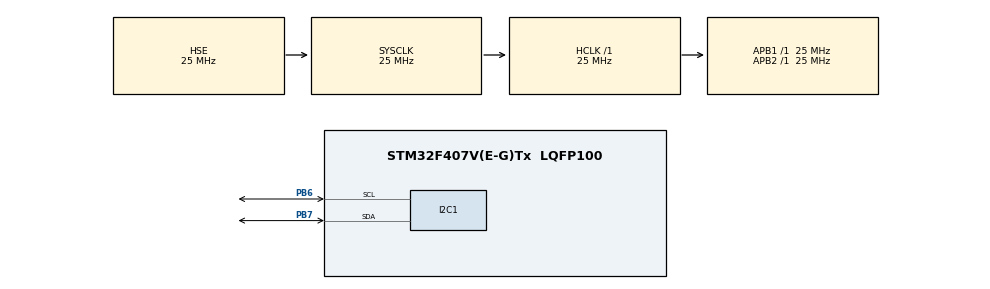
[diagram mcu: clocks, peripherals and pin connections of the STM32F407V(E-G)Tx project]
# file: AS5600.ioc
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I2C1.I2C_Mode=I2C_Standard
Mcu.Family=STM32F4
Mcu.Name=STM32F407V(E-G)Tx
Mcu.Package=LQFP100
NVIC.PriorityGroup=NVIC_PRIORITYGROUP_4
PA13.Mode=Serial_Wire
PA13.Signal=SYS_JTMS-SWDIO
PA14.Mode=Serial_Wire
PA14.Signal=SYS_JTCK-SWCLK
PB6.Mode=I2C
PB6.Signal=I2C1_SCL
PB7.Mode=I2C
PB7.Signal=I2C1_SDA
PH0-OSC_IN.Mode=HSE-External-Oscillator
PH0-OSC_IN.Signal=RCC_OSC_IN
PH1-OSC_OUT.Mode=HSE-External-Oscillator
PH1-OSC_OUT.Signal=RCC_OSC_OUT
ProjectManager.HeapSize=0x200
ProjectManager.StackSize=0x400
ProjectManager.TargetToolchain=MDK-ARM V5.32
RCC.48MHZClocksFreq_Value=75000000
RCC.AHBFreq_Value=25000000
RCC.APB1Freq_Value=25000000
RCC.APB1TimFreq_Value=25000000
RCC.APB2Freq_Value=25000000
RCC.APB2TimFreq_Value=25000000
RCC.CortexFreq_Value=25000000
RCC.HCLKFreq_Value=25000000
RCC.HSE_VALUE=25000000
RCC.HSI_VALUE=16000000
RCC.LSE_VALUE=32768
RCC.PLLSourceVirtual=RCC_PLLSOURCE_HSE
RCC.SYSCLKFreq_VALUE=25000000
RCC.SYSCLKSource=RCC_SYSCLKSOURCE_HSE
RCC.VCOOutputFreq_Value=300000000
board=custom

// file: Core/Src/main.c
/* USER CODE BEGIN Header */
/**
  ******************************************************************************
  * @file           : main.c
  * @brief          : Main program body
  ******************************************************************************
  * @attention
  *
  * Copyright (c) 2025 STMicroelectronics.
  * All rights reserved.
  *
  * This software is licensed under terms that can be found in the LICENSE file
  * in the root directory of this software component.
  * If no LICENSE file comes with this software, it is provided AS-IS.
  *
  ******************************************************************************
  */
/* USER CODE END Header */
#include "main.h"
#include "i2c.h"
#include "gpio.h"

/* USER CODE BEGIN PD */
#define AS5600_ADDR 0x36<<1   // HAL uses 8-bit address
#define AD5600_status    0x0B
#define AS5600_RAW_ANGLE 0x0C

/* USER CODE END PD */

/* USER CODE BEGIN PV */

uint8_t status=0,AGC=0;
uint16_t angle,Magnitude,P;
float r;
/* USER CODE END PV */

void SystemClock_Config(void);

/* USER CODE BEGIN 0 */
uint16_t AS5600_ReadRawAngle(void)
{
//   uint8_t high, low;
//	  HAL_I2C_Mem_Read(&hi2c1, AS5600_ADDR, 0x0C, I2C_MEMADD_SIZE_8BIT, &high, 1, 100);
//   HAL_I2C_Mem_Read(&hi2c1, AS5600_ADDR, 0x0D, I2C_MEMADD_SIZE_8BIT, &low, 1, 100);
//	 angle= (high << 8) | low;
    uint8_t buf[2];
    HAL_I2C_Mem_Read(&hi2c1, AS5600_ADDR, 0x0C, I2C_MEMADD_SIZE_8BIT, buf, 2, 100);
    angle = ((uint16_t)buf[0]<<8) | buf[1];
    return angle;
}

uint8_t  AS5600_status(void)
{
	 uint8_t s;
   HAL_I2C_Mem_Read(&hi2c1, AS5600_ADDR, 0x0B, I2C_MEMADD_SIZE_8BIT, &s, 1, 100);
   status=s;
    return status;
}

uint8_t  AS5600_AGC(void)
{
	 uint8_t s;
   HAL_I2C_Mem_Read(&hi2c1, AS5600_ADDR, 0x1A, I2C_MEMADD_SIZE_8BIT, &s, 1, 100);
   AGC=s;
    return AGC;
}

uint16_t AS5600_GetMagnitude(void)
{
		uint8_t buf[2];
    HAL_I2C_Mem_Read(&hi2c1, AS5600_ADDR, 0x1B, I2C_MEMADD_SIZE_8BIT, buf, 2, 100);
    Magnitude = ((uint16_t)buf[0]<<8) | buf[1];
    return Magnitude ;
}
/***************************** Angle Programming I2C********************/
void Write_ZPOS(void){
	AS5600_ReadRawAngle();
	uint8_t buf[2];
	buf[0] = angle >> 8;      // High byte
  buf[1] = angle & 0xFF;

	HAL_I2C_Mem_Write(&hi2c1,AS5600_ADDR,0x01,I2C_MEMADD_SIZE_8BIT,buf,2,100);
	HAL_Delay(10);
}

void Write_MPOS(void){
	AS5600_ReadRawAngle();
	uint8_t buf[2];
	buf[0] = angle >> 8;      // High byte
  buf[1] = angle & 0xFF;

  HAL_I2C_Mem_Write(&hi2c1,AS5600_ADDR,0x03,I2C_MEMADD_SIZE_8BIT,buf,2,100);
	HAL_Delay(10);

}

void AS5600_BurnAngle(void) {
    uint8_t cmd = 0x80;
    HAL_I2C_Mem_Write(&hi2c1, AS5600_ADDR, 0xFF, I2C_MEMADD_SIZE_8BIT, &cmd, 1, 100);
    HAL_Delay(10);
}

void verify_OTP(void){
uint8_t seq1 = 0x01;
HAL_I2C_Mem_Write(&hi2c1, 0x36<<1, 0xFF, I2C_MEMADD_SIZE_8BIT, &seq1, 1, 100);

uint8_t seq2 = 0x11;
HAL_I2C_Mem_Write(&hi2c1, 0x36<<1, 0xFF, I2C_MEMADD_SIZE_8BIT, &seq2, 1, 100);

uint8_t seq3 = 0x10;
HAL_I2C_Mem_Write(&hi2c1, 0x36<<1, 0xFF, I2C_MEMADD_SIZE_8BIT, &seq3, 1, 100);
}

/****Reading ZPOS & MPOS****/
uint16_t Read_Position(uint8_t reg){
	  uint8_t buf[2];
    HAL_I2C_Mem_Read(&hi2c1, AS5600_ADDR, (uint16_t)&reg, I2C_MEMADD_SIZE_8BIT, buf, 2, 100);
    P= ((uint16_t)buf[0]<<8) | buf[1];
    return P;
}
/********************************************************************************************/
/* USER CODE END 0 */

int main(void)
{

  /* MCU Configuration--------------------------------------------------------*/

  /* Reset of all peripherals, Initializes the Flash interface and the Systick. */
  HAL_Init();

  /* Configure the system clock */
  SystemClock_Config();

  /* Initialize all configured peripherals */
  MX_GPIO_Init();
  MX_I2C1_Init();

  /* Infinite loop */
  /* USER CODE BEGIN WHILE */
  while (1)
  {
		AS5600_status();
		AS5600_AGC();
		AS5600_GetMagnitude();
		r=(360.0f*AS5600_ReadRawAngle())/4095.0f;
		HAL_Delay(50);

    /* USER CODE END WHILE */

  }
}

void SystemClock_Config(void)
{
  RCC_OscInitTypeDef RCC_OscInitStruct = {0};
  RCC_ClkInitTypeDef RCC_ClkInitStruct = {0};

  /** Configure the main internal regulator output voltage
  */
  __HAL_RCC_PWR_CLK_ENABLE();
  __HAL_PWR_VOLTAGESCALING_CONFIG(PWR_REGULATOR_VOLTAGE_SCALE1);

  /** Initializes the RCC Oscillators according to the specified parameters
  * in the RCC_OscInitTypeDef structure.
  */
  RCC_OscInitStruct.OscillatorType = RCC_OSCILLATORTYPE_HSE;
  RCC_OscInitStruct.HSEState = RCC_HSE_ON;
  RCC_OscInitStruct.PLL.PLLState = RCC_PLL_NONE;
  if (HAL_RCC_OscConfig(&RCC_OscInitStruct) != HAL_OK)
  {
    Error_Handler();
  }

  /** Initializes the CPU, AHB and APB buses clocks
  */
  RCC_ClkInitStruct.ClockType = RCC_CLOCKTYPE_HCLK|RCC_CLOCKTYPE_SYSCLK
                              |RCC_CLOCKTYPE_PCLK1|RCC_CLOCKTYPE_PCLK2;
  RCC_ClkInitStruct.SYSCLKSource = RCC_SYSCLKSOURCE_HSE;
  RCC_ClkInitStruct.AHBCLKDivider = RCC_SYSCLK_DIV1;
  RCC_ClkInitStruct.APB1CLKDivider = RCC_HCLK_DIV1;
  RCC_ClkInitStruct.APB2CLKDivider = RCC_HCLK_DIV1;

  if (HAL_RCC_ClockConfig(&RCC_ClkInitStruct, FLASH_LATENCY_0) != HAL_OK)
  {
    Error_Handler();
  }
}

void Error_Handler(void)
{
  __disable_irq();
  while (1)
  {
  }
}
